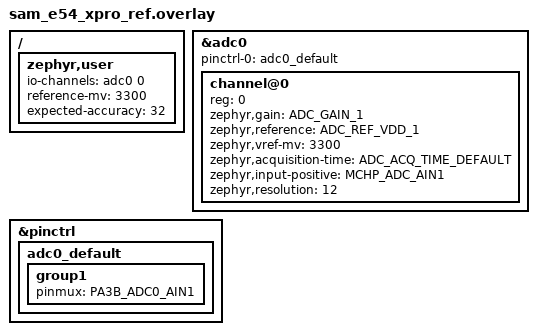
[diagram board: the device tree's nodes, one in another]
/*
 * Copyright (c) 2026 Microchip Technology Inc.
 *
 * SPDX-License-Identifier: Apache-2.0
 */

/* Connect the PA03(EXT2 pin 4) to VCC for the test */

/ {
	zephyr,user {
		io-channels = <&adc0 0>;
		reference-mv = <3300>;
		expected-accuracy = <32>;
	};
};

&adc0 {
	#address-cells = <1>;
	#size-cells = <0>;
	status = "okay";

	pinctrl-0 = <&adc0_default>;
	pinctrl-names = "default";

	channel@0 {
		reg = <0>;
		zephyr,gain = "ADC_GAIN_1";
		zephyr,reference = "ADC_REF_VDD_1";
		zephyr,vref-mv = <3300>;
		zephyr,acquisition-time = <ADC_ACQ_TIME_DEFAULT>;
		zephyr,input-positive = <MCHP_ADC_AIN1>;
		zephyr,resolution = <12>;
	};
};

&pinctrl {
	adc0_default: adc0_default {
		group1 {
			pinmux = <PA3B_ADC0_AIN1>;
		};
	};
};
